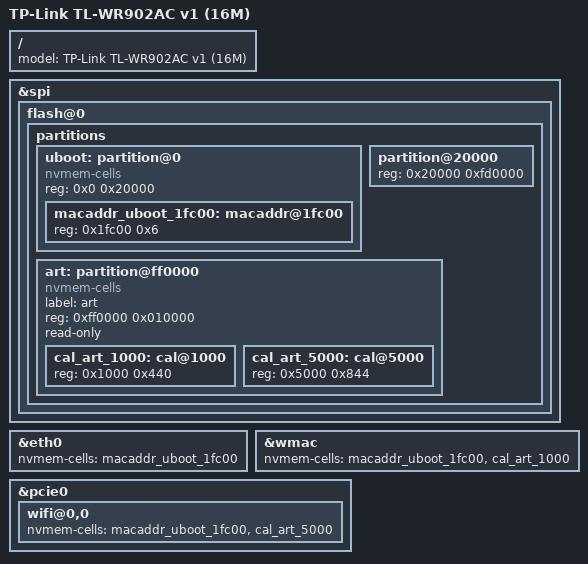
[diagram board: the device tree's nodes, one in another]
// SPDX-License-Identifier: GPL-2.0-or-later OR MIT
/dts-v1/;

#include "qca9531_tplink_tl-wr902ac-v1.dts"

/ {
	model = "TP-Link TL-WR902AC v1 (16M)";
};

&spi {
	flash@0 {
		partitions {
			uboot: partition@0 {
				reg = <0x0 0x20000>;
			};

			partition@20000 {
				reg = <0x20000 0xfd0000>;
			};

			/delete-node/ partition@750000;
			/delete-node/ partition@760000;

			/delete-node/ partition@7f0000;
			art: partition@ff0000 {
				label = "art";
				reg = <0xff0000 0x010000>;
				read-only;
			};
		};
	};
};

&art {
	compatible = "nvmem-cells";
	#address-cells = <1>;
	#size-cells = <1>;

	cal_art_1000: cal@1000 {
		reg = <0x1000 0x440>;
	};

	cal_art_5000: cal@5000 {
		reg = <0x5000 0x844>;
	};
};

&uboot {
	compatible = "nvmem-cells";
	#address-cells = <1>;
	#size-cells = <1>;

	macaddr_uboot_1fc00: macaddr@1fc00 {
		reg = <0x1fc00 0x6>;
	};
};

&eth0 {
	nvmem-cells = <&macaddr_uboot_1fc00>;
};

&wmac {
	nvmem-cells = <&macaddr_uboot_1fc00>, <&cal_art_1000>;
};

&pcie0 {
	wifi@0,0 {
		nvmem-cells = <&macaddr_uboot_1fc00>, <&cal_art_5000>;
	};
};
